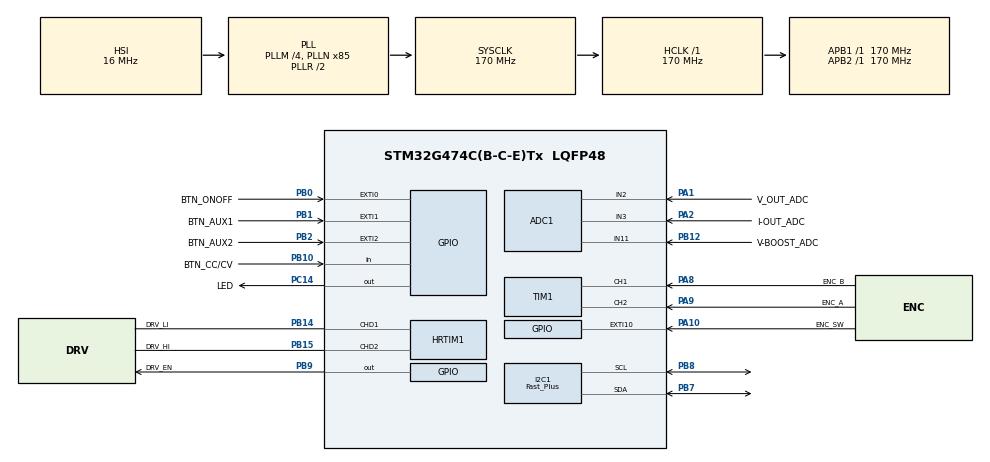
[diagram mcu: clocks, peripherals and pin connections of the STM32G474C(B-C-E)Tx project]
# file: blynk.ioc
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ADC1.Channel-0\#ChannelRegularConversion=ADC_CHANNEL_2
ADC1.Channel-1\#ChannelRegularConversion=ADC_CHANNEL_3
ADC1.Channel-2\#ChannelRegularConversion=ADC_CHANNEL_11
ADC1.ContinuousConvMode=DISABLE
ADC1.DMAContinuousRequests=ENABLE
ADC1.EOCSelection=ADC_EOC_SEQ_CONV
ADC1.ExternalTrigConv=ADC_EXTERNALTRIG_HRTIM_TRG1
ADC1.NbrOfConversion=3
ADC1.NbrOfConversionFlag=1
ADC1.OffsetNumber-0\#ChannelRegularConversion=ADC_OFFSET_NONE
ADC1.OffsetNumber-1\#ChannelRegularConversion=ADC_OFFSET_NONE
ADC1.OffsetNumber-2\#ChannelRegularConversion=ADC_OFFSET_NONE
ADC1.Overrun=ADC_OVR_DATA_PRESERVED
ADC1.OversamplingMode=DISABLE
ADC1.Rank-0\#ChannelRegularConversion=1
ADC1.Rank-1\#ChannelRegularConversion=2
ADC1.Rank-2\#ChannelRegularConversion=3
ADC1.SamplingTime-0\#ChannelRegularConversion=ADC_SAMPLETIME_24CYCLES_5
ADC1.SamplingTime-1\#ChannelRegularConversion=ADC_SAMPLETIME_24CYCLES_5
ADC1.SamplingTime-2\#ChannelRegularConversion=ADC_SAMPLETIME_24CYCLES_5
ADC1.master=1
Dma.ADC1.0.Direction=DMA_PERIPH_TO_MEMORY
Dma.ADC1.0.EventEnable=DISABLE
Dma.ADC1.0.Instance=DMA1_Channel5
Dma.ADC1.0.MemDataAlignment=DMA_MDATAALIGN_HALFWORD
Dma.ADC1.0.MemInc=DMA_MINC_ENABLE
Dma.ADC1.0.Mode=DMA_CIRCULAR
Dma.ADC1.0.PeriphDataAlignment=DMA_PDATAALIGN_HALFWORD
Dma.ADC1.0.PeriphInc=DMA_PINC_DISABLE
Dma.ADC1.0.Polarity=HAL_DMAMUX_REQ_GEN_RISING
Dma.ADC1.0.Priority=DMA_PRIORITY_HIGH
Dma.ADC1.0.RequestNumber=1
Dma.ADC1.0.SignalID=NONE
Dma.ADC1.0.SyncEnable=DISABLE
Dma.ADC1.0.SyncPolarity=HAL_DMAMUX_SYNC_NO_EVENT
Dma.ADC1.0.SyncRequestNumber=1
Dma.ADC1.0.SyncSignalID=NONE
Dma.Request0=ADC1
HRTIM1.ADCTrigger1_Source1=HRTIM_ADCTRIGGEREVENT13_TIMERD_CMP3
HRTIM1.ADCTrigger_Id1=HRTIM_ADCTRIGGER_1
HRTIM1.ADCTrigger_Id2=__NULL
HRTIM1.ChopperModeconfig-Output_TD1TD2=__NULL
HRTIM1.CompareUnit1-Output_TD1TD2=HRTIM_COMPAREUNIT_1
HRTIM1.CompareUnit2-Output_TD1TD2=__NULL
HRTIM1.CompareUnit3-Output_TD1TD2=HRTIM_COMPAREUNIT_3
HRTIM1.CompareValue1-Output_TD1TD2=544
HRTIM1.CompareValue3-Output_TD1TD2=13872
HRTIM1.DeadTimeInsertion-Output_TD1TD2=HRTIM_TIMDEADTIMEINSERTION_ENABLED
HRTIM1.Deadtimeconfig-Output_TD1TD2=HRTIM_TIMERINDEX_TIMER_D
HRTIM1.FallingValue-Output_TD1TD2=50
HRTIM1.NumberADCTriggerSource1=1
HRTIM1.NumberResetSource1-Output_TD1TD2=1
HRTIM1.NumberResetSource2_TD=0
HRTIM1.NumberSetSource1-Output_TD1TD2=1
HRTIM1.NumberSetSource2_TD=0
HRTIM1.ORingUpdateSource_ADCTrigger1=HRTIM_ADCTRIGGERUPDATE_TIMER_D
HRTIM1.Periode_MASTER=27200
HRTIM1.Periode_TD=27200
HRTIM1.Polarity1-Output_TD1TD2=HRTIM_OUTPUTPOLARITY_HIGH
HRTIM1.Polarity2-Output_TD1TD2=HRTIM_OUTPUTPOLARITY_HIGH
HRTIM1.PreloadEnable-Output_TD1TD2=HRTIM_PRELOAD_ENABLED
HRTIM1.PrescalerDead-Output_TD1TD2=HRTIM_TIMDEADTIME_PRESCALERRATIO_MUL8
HRTIM1.PrescalerRatio_TD=HRTIM_PRESCALERRATIO_MUL32
HRTIM1.PushPull-Output_TD1TD2=HRTIM_TIMPUSHPULLMODE_DISABLED
HRTIM1.ResetOutput1_Source1-Output_TD1TD2=HRTIM_OUTPUTRESET_TIMPER
HRTIM1.RisingValue-Output_TD1TD2=500
HRTIM1.SetOutput1_Source1-Output_TD1TD2=HRTIM_OUTPUTSET_TIMCMP1
HRTIM1.postscaler1=3
I2C1.Analog_Filter=I2C_ANALOGFILTER_ENABLE
I2C1.CustomTiming=Disabled
I2C1.I2C_Fall_Time=20
I2C1.I2C_Rise_Time=20
I2C1.I2C_Speed_Mode=I2C_Fast_Plus
I2C1.Timing=0x00B02369
Mcu.Family=STM32G4
Mcu.Name=STM32G474C(B-C-E)Tx
Mcu.Package=LQFP48
NVIC.ADC1_2_IRQn=true\:1\:0\:false\:false\:true\:true\:true\:true
NVIC.DMA1_Channel5_IRQn=true\:1\:0\:false\:false\:true\:false\:true\:true
NVIC.EXTI0_IRQn=true\:0\:0\:false\:false\:true\:true\:true\:true
NVIC.EXTI15_10_IRQn=true\:0\:0\:false\:false\:true\:true\:true\:true
NVIC.EXTI1_IRQn=true\:0\:0\:false\:false\:true\:true\:true\:true
NVIC.EXTI2_IRQn=true\:0\:0\:false\:false\:true\:true\:true\:true
NVIC.I2C1_EV_IRQn=true\:0\:0\:false\:false\:true\:true\:true\:true
NVIC.PriorityGroup=NVIC_PRIORITYGROUP_4
NVIC.TIM1_BRK_TIM15_IRQn=true\:0\:0\:false\:false\:true\:true\:true\:true
NVIC.TIM1_CC_IRQn=true\:0\:0\:false\:false\:true\:true\:true\:true
NVIC.TIM1_TRG_COM_TIM17_IRQn=true\:0\:0\:false\:false\:true\:true\:true\:true
NVIC.TIM1_UP_TIM16_IRQn=true\:0\:0\:false\:false\:true\:true\:true\:true
NVIC.TIM2_IRQn=true\:0\:0\:false\:false\:true\:true\:true\:true
PA1.GPIO_Label=V_OUT_ADC
PA1.Mode=IN2-Single-Ended
PA1.Signal=ADC1_IN2
PA10.GPIO_Label=ENC_SW
PA10.GPIO_ModeDefaultEXTI=GPIO_MODE_IT_RISING_FALLING
PA10.GPIO_PuPd=GPIO_PULLDOWN
PA10.Signal=GPXTI10
PA13.Mode=Serial_Wire
PA13.Signal=SYS_JTMS-SWDIO
PA14.Mode=Serial_Wire
PA14.Signal=SYS_JTCK-SWCLK
PA2.GPIO_Label=I-OUT_ADC
PA2.Mode=IN3-Single-Ended
PA2.Signal=ADC1_IN3
PA8.GPIO_Label=ENC_B
PA8.GPIO_PuPd=GPIO_PULLUP
PA8.Signal=S_TIM1_CH1
PA9.GPIO_Label=ENC_A
PA9.GPIO_PuPd=GPIO_PULLUP
PA9.Signal=S_TIM1_CH2
PB0.GPIO_Label=BTN_ONOFF
PB0.GPIO_ModeDefaultEXTI=GPIO_MODE_IT_RISING_FALLING
PB0.GPIO_PuPd=GPIO_PULLUP
PB0.Signal=GPXTI0
PB1.GPIO_Label=BTN_AUX1
PB1.GPIO_ModeDefaultEXTI=GPIO_MODE_IT_RISING_FALLING
PB1.GPIO_PuPd=GPIO_PULLUP
PB1.Signal=GPXTI1
PB10.GPIO_Label=BTN_CC/CV
PB10.Signal=GPIO_Input
PB12.GPIO_Label=V-BOOST_ADC
PB12.Mode=IN11-Single-Ended
PB12.Signal=ADC1_IN11
PB14.GPIO_Label=DRV_LI
PB14.Mode=Output_TD1TD2
PB14.Signal=HRTIM1_CHD1
PB15.GPIO_Label=DRV_HI
PB15.Mode=Output_TD1TD2
PB15.Signal=HRTIM1_CHD2
PB2.GPIO_Label=BTN_AUX2
PB2.GPIO_ModeDefaultEXTI=GPIO_MODE_IT_RISING_FALLING
PB2.GPIO_PuPd=GPIO_PULLUP
PB2.Signal=GPXTI2
PB7.GPIO_FM7=SYSCFG_FASTMODEPLUS_PB7
PB7.GPIO_Pu=GPIO_PULLUP
PB7.GPIO_Speed=GPIO_SPEED_FREQ_VERY_HIGH
PB7.Mode=I2C
PB7.Signal=I2C1_SDA
PB8-BOOT0.GPIO_FM8=SYSCFG_FASTMODEPLUS_PB8
PB8-BOOT0.GPIO_Pu=GPIO_PULLUP
PB8-BOOT0.GPIO_Speed=GPIO_SPEED_FREQ_VERY_HIGH
PB8-BOOT0.Mode=I2C
PB8-BOOT0.Signal=I2C1_SCL
PB9.GPIO_Label=DRV_EN
PB9.Signal=GPIO_Output
PC14-OSC32_IN.GPIO_Label=LED
PC14-OSC32_IN.Signal=GPIO_Output
PF0-OSC_IN.Mode=HSE-External-Oscillator
PF0-OSC_IN.Signal=RCC_OSC_IN
PF1-OSC_OUT.Mode=HSE-External-Oscillator
PF1-OSC_OUT.Signal=RCC_OSC_OUT
ProjectManager.HeapSize=0x200
ProjectManager.StackSize=0x400
ProjectManager.TargetToolchain=CMake
RCC.ADC12Freq_Value=170000000
RCC.ADC345Freq_Value=170000000
RCC.AHBFreq_Value=170000000
RCC.APB1Freq_Value=170000000
RCC.APB1TimFreq_Value=170000000
RCC.APB2Freq_Value=170000000
RCC.APB2TimFreq_Value=170000000
RCC.CK48CLockSelection=RCC_USBCLKSOURCE_HSI48
RCC.CortexFreq_Value=170000000
RCC.EXTERNAL_CLOCK_VALUE=12288000
RCC.HCLKFreq_Value=170000000
RCC.HSE_VALUE=8000000
RCC.HSI48_VALUE=48000000
RCC.HSI_VALUE=16000000
RCC.LSE_VALUE=32768
RCC.PLLM=RCC_PLLM_DIV4
RCC.PLLN=85
RCC.PLLQ=RCC_PLLQ_DIV6
RCC.SYSCLKFreq_VALUE=170000000
RCC.SYSCLKSource=RCC_SYSCLKSOURCE_PLLCLK
RCC.USBFreq_Value=48000000
RCC.VCOOutputFreq_Value=340000000
SH.S_TIM1_CH1.0=TIM1_CH1,Encoder_Interface
SH.S_TIM1_CH2.0=TIM1_CH2,Encoder_Interface
TIM1.EncoderMode=TIM_ENCODERMODE_TI12
TIM1.IC1Filter=15
TIM1.IC2Filter=15
TIM2.PeriodNoDither=3400-1
TIM2.Prescaler=0
TIM2.TIM_MasterOutputTrigger=TIM_TRGO_UPDATE
VP_HRTIM1_VS_hrtimMasterTimerNoOutput.Mode=MasterTimer
VP_SYS_VS_DBSignals.Mode=DisableDeadBatterySignals
VP_TIM2_VS_ClockSourceINT.Mode=Internal
board=custom

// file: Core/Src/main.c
/* USER CODE BEGIN Header */
/**
 ******************************************************************************
 * @file           : main.c
 * @brief          : Main program body
 ******************************************************************************
 * @attention
 *
 * Copyright (c) 2025 STMicroelectronics.
 * All rights reserved.
 *
 * This software is licensed under terms that can be found in the LICENSE file
 * in the root directory of this software component.
 * If no LICENSE file comes with this software, it is provided AS-IS.
 *
 ******************************************************************************
 */
/* USER CODE END Header */
#include "main.h"

/* USER CODE BEGIN Includes */
#include "app.h"
#include "psu_config.h"
/* USER CODE END Includes */

ADC_HandleTypeDef hadc1;
DMA_HandleTypeDef hdma_adc1;

HRTIM_HandleTypeDef hhrtim1;

I2C_HandleTypeDef hi2c1;

TIM_HandleTypeDef htim1;
TIM_HandleTypeDef htim2;

void SystemClock_Config(void);
static void MX_GPIO_Init(void);
static void MX_DMA_Init(void);
static void MX_ADC1_Init(void);
static void MX_HRTIM1_Init(void);
static void MX_I2C1_Init(void);
static void MX_TIM2_Init(void);
static void MX_TIM1_Init(void);

int main(void)
{

  /* USER CODE BEGIN 1 */
  SCB->VTOR = FLASH_BASE;
  /* USER CODE END 1 */

  /* MCU Configuration--------------------------------------------------------*/

  /* Reset of all peripherals, Initializes the Flash interface and the Systick. */
  HAL_Init();

  /* Configure the system clock */
  SystemClock_Config();

  /* Initialize all configured peripherals */
  MX_GPIO_Init();
  MX_DMA_Init();
  MX_ADC1_Init();
  MX_HRTIM1_Init();
  MX_I2C1_Init();
  MX_TIM2_Init();
  MX_TIM1_Init();
  /* USER CODE BEGIN 2 */

  APP_Init();
  /* USER CODE END 2 */

  /* Infinite loop */
  while (1) {

    /* USER CODE BEGIN 3 */

    APP_Run();
  }
  /* USER CODE END 3 */
}

void SystemClock_Config(void)
{
  RCC_OscInitTypeDef RCC_OscInitStruct = {0};
  RCC_ClkInitTypeDef RCC_ClkInitStruct = {0};

  /** Configure the main internal regulator output voltage
  */
  HAL_PWREx_ControlVoltageScaling(PWR_REGULATOR_VOLTAGE_SCALE1_BOOST);

  /** Initializes the RCC Oscillators according to the specified parameters
  * in the RCC_OscInitTypeDef structure.
  */
  RCC_OscInitStruct.OscillatorType = RCC_OSCILLATORTYPE_HSI;
  RCC_OscInitStruct.HSIState = RCC_HSI_ON;
  RCC_OscInitStruct.HSICalibrationValue = RCC_HSICALIBRATION_DEFAULT;
  RCC_OscInitStruct.PLL.PLLState = RCC_PLL_ON;
  RCC_OscInitStruct.PLL.PLLSource = RCC_PLLSOURCE_HSI;
  RCC_OscInitStruct.PLL.PLLM = RCC_PLLM_DIV4;
  RCC_OscInitStruct.PLL.PLLN = 85;
  RCC_OscInitStruct.PLL.PLLP = RCC_PLLP_DIV2;
  RCC_OscInitStruct.PLL.PLLQ = RCC_PLLQ_DIV6;
  RCC_OscInitStruct.PLL.PLLR = RCC_PLLR_DIV2;
  if (HAL_RCC_OscConfig(&RCC_OscInitStruct) != HAL_OK)
  {
    Error_Handler();
  }

  /** Initializes the CPU, AHB and APB buses clocks
  */
  RCC_ClkInitStruct.ClockType = RCC_CLOCKTYPE_HCLK|RCC_CLOCKTYPE_SYSCLK
                              |RCC_CLOCKTYPE_PCLK1|RCC_CLOCKTYPE_PCLK2;
  RCC_ClkInitStruct.SYSCLKSource = RCC_SYSCLKSOURCE_PLLCLK;
  RCC_ClkInitStruct.AHBCLKDivider = RCC_SYSCLK_DIV1;
  RCC_ClkInitStruct.APB1CLKDivider = RCC_HCLK_DIV1;
  RCC_ClkInitStruct.APB2CLKDivider = RCC_HCLK_DIV1;

  if (HAL_RCC_ClockConfig(&RCC_ClkInitStruct, FLASH_LATENCY_4) != HAL_OK)
  {
    Error_Handler();
  }
}

static void MX_ADC1_Init(void)
{

  ADC_MultiModeTypeDef multimode = {0};
  ADC_ChannelConfTypeDef sConfig = {0};

  /** Common config
  */
  hadc1.Instance = ADC1;
  hadc1.Init.ClockPrescaler = ADC_CLOCK_SYNC_PCLK_DIV4;
  hadc1.Init.Resolution = ADC_RESOLUTION_12B;
  hadc1.Init.DataAlign = ADC_DATAALIGN_RIGHT;
  hadc1.Init.GainCompensation = 0;
  hadc1.Init.ScanConvMode = ADC_SCAN_ENABLE;
  hadc1.Init.EOCSelection = ADC_EOC_SEQ_CONV;
  hadc1.Init.LowPowerAutoWait = DISABLE;
  hadc1.Init.ContinuousConvMode = DISABLE;
  hadc1.Init.NbrOfConversion = 3;
  hadc1.Init.DiscontinuousConvMode = DISABLE;
  hadc1.Init.ExternalTrigConv = ADC_EXTERNALTRIG_HRTIM_TRG1;
  hadc1.Init.ExternalTrigConvEdge = ADC_EXTERNALTRIGCONVEDGE_RISING;
  hadc1.Init.DMAContinuousRequests = ENABLE;
  hadc1.Init.Overrun = ADC_OVR_DATA_PRESERVED;
  hadc1.Init.OversamplingMode = DISABLE;
  if (HAL_ADC_Init(&hadc1) != HAL_OK)
  {
    Error_Handler();
  }

  /** Configure the ADC multi-mode
  */
  multimode.Mode = ADC_MODE_INDEPENDENT;
  if (HAL_ADCEx_MultiModeConfigChannel(&hadc1, &multimode) != HAL_OK)
  {
    Error_Handler();
  }

  /** Configure Regular Channel
  */
  sConfig.Channel = ADC_CHANNEL_2;
  sConfig.Rank = ADC_REGULAR_RANK_1;
  /*
   * TODO: verify divider Thevenin resistance on the schematic.
   * With the known 1 nF input filter, 24.5 cycles is a safer starting point
   * than 12.5 cycles until Rth*C and ADC acquisition settling are confirmed.
   */
  sConfig.SamplingTime = ADC_SAMPLETIME_24CYCLES_5;
  sConfig.SingleDiff = ADC_SINGLE_ENDED;
  sConfig.OffsetNumber = ADC_OFFSET_NONE;
  sConfig.Offset = 0;
  if (HAL_ADC_ConfigChannel(&hadc1, &sConfig) != HAL_OK)
  {
    Error_Handler();
  }

  /** Configure Regular Channel
  */
  sConfig.Channel = ADC_CHANNEL_3;
  sConfig.Rank = ADC_REGULAR_RANK_2;
  if (HAL_ADC_ConfigChannel(&hadc1, &sConfig) != HAL_OK)
  {
    Error_Handler();
  }

  /** Configure Regular Channel
  */
  sConfig.Channel = ADC_CHANNEL_11;
  sConfig.Rank = ADC_REGULAR_RANK_3;
  if (HAL_ADC_ConfigChannel(&hadc1, &sConfig) != HAL_OK)
  {
    Error_Handler();
  }

}

static void MX_HRTIM1_Init(void)
{

  HRTIM_ADCTriggerCfgTypeDef pADCTriggerCfg = {0};
  HRTIM_TimeBaseCfgTypeDef pTimeBaseCfg = {0};
  HRTIM_TimerCfgTypeDef pTimerCfg = {0};
  HRTIM_TimerCtlTypeDef pTimerCtl = {0};
  HRTIM_CompareCfgTypeDef pCompareCfg = {0};
  HRTIM_DeadTimeCfgTypeDef pDeadTimeCfg = {0};
  HRTIM_OutputCfgTypeDef pOutputCfg = {0};

  hhrtim1.Instance = HRTIM1;
  hhrtim1.Init.HRTIMInterruptResquests = HRTIM_IT_NONE;
  hhrtim1.Init.SyncOptions = HRTIM_SYNCOPTION_NONE;
  if (HAL_HRTIM_Init(&hhrtim1) != HAL_OK)
  {
    Error_Handler();
  }
  if (HAL_HRTIM_DLLCalibrationStart(&hhrtim1, HRTIM_CALIBRATIONRATE_3) != HAL_OK)
  {
    Error_Handler();
  }
  if (HAL_HRTIM_PollForDLLCalibration(&hhrtim1, 10) != HAL_OK)
  {
    Error_Handler();
  }
  pADCTriggerCfg.UpdateSource = HRTIM_ADCTRIGGERUPDATE_TIMER_D;
  pADCTriggerCfg.Trigger = HRTIM_ADCTRIGGEREVENT13_TIMERD_CMP3;
  if (HAL_HRTIM_ADCTriggerConfig(&hhrtim1, HRTIM_ADCTRIGGER_1, &pADCTriggerCfg) != HAL_OK)
  {
    Error_Handler();
  }
  if (HAL_HRTIM_ADCPostScalerConfig(&hhrtim1,
                                    HRTIM_ADCTRIGGER_1,
                                    HRTIM_ADC_POSTSCALER) != HAL_OK)
  {
    Error_Handler();
  }
  pTimeBaseCfg.Period = 27200;
  pTimeBaseCfg.RepetitionCounter = 0x00;
  pTimeBaseCfg.PrescalerRatio = HRTIM_PRESCALERRATIO_MUL32;
  pTimeBaseCfg.Mode = HRTIM_MODE_CONTINUOUS;
  if (HAL_HRTIM_TimeBaseConfig(&hhrtim1, HRTIM_TIMERINDEX_MASTER, &pTimeBaseCfg) != HAL_OK)
  {
    Error_Handler();
  }
  pTimerCfg.InterruptRequests = HRTIM_MASTER_IT_NONE;
  pTimerCfg.DMARequests = HRTIM_MASTER_DMA_NONE;
  pTimerCfg.DMASrcAddress = 0x0000;
  pTimerCfg.DMADstAddress = 0x0000;
  pTimerCfg.DMASize = 0x1;
  pTimerCfg.HalfModeEnable = HRTIM_HALFMODE_DISABLED;
  pTimerCfg.InterleavedMode = HRTIM_INTERLEAVED_MODE_DISABLED;
  pTimerCfg.StartOnSync = HRTIM_SYNCSTART_DISABLED;
  pTimerCfg.ResetOnSync = HRTIM_SYNCRESET_DISABLED;
  pTimerCfg.DACSynchro = HRTIM_DACSYNC_NONE;
  pTimerCfg.PreloadEnable = HRTIM_PRELOAD_ENABLED;
  pTimerCfg.UpdateGating = HRTIM_UPDATEGATING_INDEPENDENT;
  pTimerCfg.BurstMode = HRTIM_TIMERBURSTMODE_MAINTAINCLOCK;
  pTimerCfg.RepetitionUpdate = HRTIM_UPDATEONREPETITION_ENABLED;
  pTimerCfg.ReSyncUpdate = HRTIM_TIMERESYNC_UPDATE_UNCONDITIONAL;
  if (HAL_HRTIM_WaveformTimerConfig(&hhrtim1, HRTIM_TIMERINDEX_MASTER, &pTimerCfg) != HAL_OK)
  {
    Error_Handler();
  }
  pTimeBaseCfg.Period = 27200;
  if (HAL_HRTIM_TimeBaseConfig(&hhrtim1, HRTIM_TIMERINDEX_TIMER_D, &pTimeBaseCfg) != HAL_OK)
  {
    Error_Handler();
  }
  pTimerCtl.UpDownMode = HRTIM_TIMERUPDOWNMODE_UP;
  pTimerCtl.GreaterCMP3 = HRTIM_TIMERGTCMP3_EQUAL;
  pTimerCtl.GreaterCMP1 = HRTIM_TIMERGTCMP1_EQUAL;
  pTimerCtl.DualChannelDacEnable = HRTIM_TIMER_DCDE_DISABLED;
  if (HAL_HRTIM_WaveformTimerControl(&hhrtim1, HRTIM_TIMERINDEX_TIMER_D, &pTimerCtl) != HAL_OK)
  {
    Error_Handler();
  }
  pTimerCfg.InterruptRequests = HRTIM_TIM_IT_NONE;
  pTimerCfg.DMARequests = HRTIM_TIM_DMA_NONE;
  pTimerCfg.PushPull = HRTIM_TIMPUSHPULLMODE_DISABLED;
  pTimerCfg.FaultEnable = HRTIM_TIMFAULTENABLE_NONE;
  pTimerCfg.FaultLock = HRTIM_TIMFAULTLOCK_READWRITE;
  pTimerCfg.DeadTimeInsertion = HRTIM_TIMDEADTIMEINSERTION_ENABLED;
  pTimerCfg.DelayedProtectionMode = HRTIM_TIMER_D_E_DELAYEDPROTECTION_DISABLED;
  pTimerCfg.UpdateTrigger = HRTIM_TIMUPDATETRIGGER_TIMER_D;
  pTimerCfg.ResetTrigger = HRTIM_TIMRESETTRIGGER_NONE;
  pTimerCfg.ResetUpdate = HRTIM_TIMUPDATEONRESET_ENABLED;
  if (HAL_HRTIM_WaveformTimerConfig(&hhrtim1, HRTIM_TIMERINDEX_TIMER_D, &pTimerCfg) != HAL_OK)
  {
    Error_Handler();
  }
  pCompareCfg.CompareValue = 544;
  if (HAL_HRTIM_WaveformCompareConfig(&hhrtim1, HRTIM_TIMERINDEX_TIMER_D, HRTIM_COMPAREUNIT_1, &pCompareCfg) != HAL_OK)
  {
    Error_Handler();
  }
  pCompareCfg.CompareValue = 13872;
  if (HAL_HRTIM_WaveformCompareConfig(&hhrtim1, HRTIM_TIMERINDEX_TIMER_D, HRTIM_COMPAREUNIT_3, &pCompareCfg) != HAL_OK)
  {
    Error_Handler();
  }
  pDeadTimeCfg.Prescaler = HRTIM_TIMDEADTIME_PRESCALERRATIO_MUL8;
  pDeadTimeCfg.RisingValue = 500;
  pDeadTimeCfg.RisingSign = HRTIM_TIMDEADTIME_RISINGSIGN_POSITIVE;
  pDeadTimeCfg.RisingLock = HRTIM_TIMDEADTIME_RISINGLOCK_WRITE;
  pDeadTimeCfg.RisingSignLock = HRTIM_TIMDEADTIME_RISINGSIGNLOCK_WRITE;
  pDeadTimeCfg.FallingValue = 50;
  pDeadTimeCfg.FallingSign = HRTIM_TIMDEADTIME_FALLINGSIGN_POSITIVE;
  pDeadTimeCfg.FallingLock = HRTIM_TIMDEADTIME_FALLINGLOCK_WRITE;
  pDeadTimeCfg.FallingSignLock = HRTIM_TIMDEADTIME_FALLINGSIGNLOCK_WRITE;
  if (HAL_HRTIM_DeadTimeConfig(&hhrtim1, HRTIM_TIMERINDEX_TIMER_D, &pDeadTimeCfg) != HAL_OK)
  {
    Error_Handler();
  }
  pOutputCfg.Polarity = HRTIM_OUTPUTPOLARITY_HIGH;
  pOutputCfg.SetSource = HRTIM_OUTPUTSET_TIMCMP1;
  pOutputCfg.ResetSource = HRTIM_OUTPUTRESET_TIMPER;
  pOutputCfg.IdleMode = HRTIM_OUTPUTIDLEMODE_NONE;
  pOutputCfg.IdleLevel = HRTIM_OUTPUTIDLELEVEL_INACTIVE;
  pOutputCfg.FaultLevel = HRTIM_OUTPUTFAULTLEVEL_NONE;
  pOutputCfg.ChopperModeEnable = HRTIM_OUTPUTCHOPPERMODE_DISABLED;
  pOutputCfg.BurstModeEntryDelayed = HRTIM_OUTPUTBURSTMODEENTRY_REGULAR;
  if (HAL_HRTIM_WaveformOutputConfig(&hhrtim1, HRTIM_TIMERINDEX_TIMER_D, HRTIM_OUTPUT_TD1, &pOutputCfg) != HAL_OK)
  {
    Error_Handler();
  }
  pOutputCfg.SetSource = HRTIM_OUTPUTSET_TIMPER;
  pOutputCfg.ResetSource = HRTIM_OUTPUTRESET_TIMCMP1;
  if (HAL_HRTIM_WaveformOutputConfig(&hhrtim1, HRTIM_TIMERINDEX_TIMER_D, HRTIM_OUTPUT_TD2, &pOutputCfg) != HAL_OK)
  {
    Error_Handler();
  }
  HAL_HRTIM_MspPostInit(&hhrtim1);

}

static void MX_I2C1_Init(void)
{

  hi2c1.Instance = I2C1;
  hi2c1.Init.Timing = 0x00B02369;
  hi2c1.Init.OwnAddress1 = 0;
  hi2c1.Init.AddressingMode = I2C_ADDRESSINGMODE_7BIT;
  hi2c1.Init.DualAddressMode = I2C_DUALADDRESS_DISABLE;
  hi2c1.Init.OwnAddress2 = 0;
  hi2c1.Init.OwnAddress2Masks = I2C_OA2_NOMASK;
  hi2c1.Init.GeneralCallMode = I2C_GENERALCALL_DISABLE;
  hi2c1.Init.NoStretchMode = I2C_NOSTRETCH_DISABLE;
  if (HAL_I2C_Init(&hi2c1) != HAL_OK)
  {
    Error_Handler();
  }

  /** Configure Analogue filter
  */
  if (HAL_I2CEx_ConfigAnalogFilter(&hi2c1, I2C_ANALOGFILTER_ENABLE) != HAL_OK)
  {
    Error_Handler();
  }

  /** Configure Digital filter
  */
  if (HAL_I2CEx_ConfigDigitalFilter(&hi2c1, 0) != HAL_OK)
  {
    Error_Handler();
  }

  /** I2C Fast mode Plus enable
  */
  HAL_I2CEx_EnableFastModePlus(I2C_FASTMODEPLUS_I2C1);

}

static void MX_TIM1_Init(void)
{

  TIM_Encoder_InitTypeDef sConfig = {0};
  TIM_MasterConfigTypeDef sMasterConfig = {0};

  htim1.Instance = TIM1;
  htim1.Init.Prescaler = 0;
  htim1.Init.CounterMode = TIM_COUNTERMODE_UP;
  htim1.Init.Period = 65535;
  htim1.Init.ClockDivision = TIM_CLOCKDIVISION_DIV1;
  htim1.Init.RepetitionCounter = 0;
  htim1.Init.AutoReloadPreload = TIM_AUTORELOAD_PRELOAD_DISABLE;
  sConfig.EncoderMode = TIM_ENCODERMODE_TI12;
  sConfig.IC1Polarity = TIM_ICPOLARITY_RISING;
  sConfig.IC1Selection = TIM_ICSELECTION_DIRECTTI;
  sConfig.IC1Prescaler = TIM_ICPSC_DIV1;
  sConfig.IC1Filter = 15;
  sConfig.IC2Polarity = TIM_ICPOLARITY_RISING;
  sConfig.IC2Selection = TIM_ICSELECTION_DIRECTTI;
  sConfig.IC2Prescaler = TIM_ICPSC_DIV1;
  sConfig.IC2Filter = 15;
  if (HAL_TIM_Encoder_Init(&htim1, &sConfig) != HAL_OK)
  {
    Error_Handler();
  }
  sMasterConfig.MasterOutputTrigger = TIM_TRGO_RESET;
  sMasterConfig.MasterOutputTrigger2 = TIM_TRGO2_RESET;
  sMasterConfig.MasterSlaveMode = TIM_MASTERSLAVEMODE_DISABLE;
  if (HAL_TIMEx_MasterConfigSynchronization(&htim1, &sMasterConfig) != HAL_OK)
  {
    Error_Handler();
  }

}

static void MX_TIM2_Init(void)
{

  TIM_ClockConfigTypeDef sClockSourceConfig = {0};
  TIM_MasterConfigTypeDef sMasterConfig = {0};

  htim2.Instance = TIM2;
  htim2.Init.Prescaler = 0;
  htim2.Init.CounterMode = TIM_COUNTERMODE_UP;
  htim2.Init.Period = 3399;
  htim2.Init.ClockDivision = TIM_CLOCKDIVISION_DIV1;
  htim2.Init.AutoReloadPreload = TIM_AUTORELOAD_PRELOAD_DISABLE;
  if (HAL_TIM_Base_Init(&htim2) != HAL_OK)
  {
    Error_Handler();
  }
  sClockSourceConfig.ClockSource = TIM_CLOCKSOURCE_INTERNAL;
  if (HAL_TIM_ConfigClockSource(&htim2, &sClockSourceConfig) != HAL_OK)
  {
    Error_Handler();
  }
  sMasterConfig.MasterOutputTrigger = TIM_TRGO_UPDATE;
  sMasterConfig.MasterSlaveMode = TIM_MASTERSLAVEMODE_DISABLE;
  if (HAL_TIMEx_MasterConfigSynchronization(&htim2, &sMasterConfig) != HAL_OK)
  {
    Error_Handler();
  }

}

static void MX_DMA_Init(void)
{

  /* DMA controller clock enable */
  __HAL_RCC_DMAMUX1_CLK_ENABLE();
  __HAL_RCC_DMA1_CLK_ENABLE();

  /* DMA interrupt init */
  /* DMA1_Channel5_IRQn interrupt configuration */
  HAL_NVIC_SetPriority(DMA1_Channel5_IRQn, 1, 0);
  HAL_NVIC_EnableIRQ(DMA1_Channel5_IRQn);

}

static void MX_GPIO_Init(void)
{
  GPIO_InitTypeDef GPIO_InitStruct = {0};

  /* GPIO Ports Clock Enable */
  __HAL_RCC_GPIOC_CLK_ENABLE();
  __HAL_RCC_GPIOF_CLK_ENABLE();
  __HAL_RCC_GPIOA_CLK_ENABLE();
  __HAL_RCC_GPIOB_CLK_ENABLE();

  /*Configure GPIO pin Output Level */
  HAL_GPIO_WritePin(LED_GPIO_Port, LED_Pin, GPIO_PIN_RESET);

  /*Configure GPIO pin Output Level */
  HAL_GPIO_WritePin(DRV_EN_GPIO_Port, DRV_EN_Pin, GPIO_PIN_RESET);

  /*Configure GPIO pin : LED_Pin */
  GPIO_InitStruct.Pin = LED_Pin;
  GPIO_InitStruct.Mode = GPIO_MODE_OUTPUT_PP;
  GPIO_InitStruct.Pull = GPIO_NOPULL;
  GPIO_InitStruct.Speed = GPIO_SPEED_FREQ_LOW;
  HAL_GPIO_Init(LED_GPIO_Port, &GPIO_InitStruct);

  /*Configure GPIO pins : BTN_ONOFF_Pin BTN_AUX1_Pin BTN_AUX2_Pin */
  GPIO_InitStruct.Pin = BTN_ONOFF_Pin|BTN_AUX1_Pin|BTN_AUX2_Pin;
  GPIO_InitStruct.Mode = GPIO_MODE_IT_RISING_FALLING;
  GPIO_InitStruct.Pull = GPIO_PULLUP;
  HAL_GPIO_Init(GPIOB, &GPIO_InitStruct);

  /*Configure GPIO pin : BTN_CC_CV_Pin */
  GPIO_InitStruct.Pin = BTN_CC_CV_Pin;
  GPIO_InitStruct.Mode = GPIO_MODE_INPUT;
  GPIO_InitStruct.Pull = GPIO_NOPULL;
  HAL_GPIO_Init(BTN_CC_CV_GPIO_Port, &GPIO_InitStruct);

  /*Configure GPIO pin : ENC_SW_Pin */
  GPIO_InitStruct.Pin = ENC_SW_Pin;
  GPIO_InitStruct.Mode = GPIO_MODE_IT_RISING_FALLING;
  GPIO_InitStruct.Pull = GPIO_PULLDOWN;
  HAL_GPIO_Init(ENC_SW_GPIO_Port, &GPIO_InitStruct);

  /*Configure GPIO pin : DRV_EN_Pin */
  GPIO_InitStruct.Pin = DRV_EN_Pin;
  GPIO_InitStruct.Mode = GPIO_MODE_OUTPUT_PP;
  GPIO_InitStruct.Pull = GPIO_NOPULL;
  GPIO_InitStruct.Speed = GPIO_SPEED_FREQ_LOW;
  HAL_GPIO_Init(DRV_EN_GPIO_Port, &GPIO_InitStruct);

  /* EXTI interrupt init*/
  HAL_NVIC_SetPriority(EXTI0_IRQn, 0, 0);
  HAL_NVIC_EnableIRQ(EXTI0_IRQn);

  HAL_NVIC_SetPriority(EXTI1_IRQn, 0, 0);
  HAL_NVIC_EnableIRQ(EXTI1_IRQn);

  HAL_NVIC_SetPriority(EXTI2_IRQn, 0, 0);
  HAL_NVIC_EnableIRQ(EXTI2_IRQn);

  HAL_NVIC_SetPriority(EXTI15_10_IRQn, 0, 0);
  HAL_NVIC_EnableIRQ(EXTI15_10_IRQn);

}

void Error_Handler(void)
{
  __disable_irq();
  while (1) {
  }
}
#ifdef USE_FULL_ASSERT
/**
  * @brief  Reports the name of the source file and the source line number
  *         where the assert_param error has occurred.
  * @param  file: pointer to the source file name
  * @param  line: assert_param error line source number
  * @retval None
  */
void assert_failed(uint8_t *file, uint32_t line)
{
  /* USER CODE BEGIN 6 */
  /* User can add his own implementation to report the file name and line
     number, ex: printf("Wrong parameters value: file %s on line %d\r\n", file,
     line) */
  /* USER CODE END 6 */
}
#endif /* USE_FULL_ASSERT */
